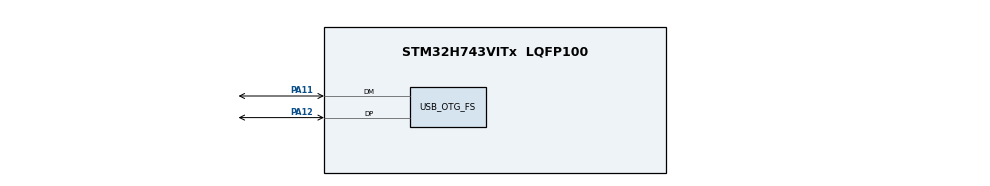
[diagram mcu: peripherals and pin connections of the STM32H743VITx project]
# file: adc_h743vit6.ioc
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Mcu.Family=STM32H7
Mcu.Name=STM32H743VITx
Mcu.Package=LQFP100
NVIC.OTG_FS_IRQn=true\:0\:0\:false\:false\:true\:false\:true
NVIC.PriorityGroup=NVIC_PRIORITYGROUP_4
PA11.Mode=Device_Only
PA11.Signal=USB_OTG_FS_DM
PA12.Mode=Device_Only
PA12.Signal=USB_OTG_FS_DP
ProjectManager.HeapSize=0x200
ProjectManager.StackSize=0x400
ProjectManager.TargetToolchain=STM32CubeIDE
RCC.ADCFreq_Value=129000000
RCC.APB1Freq_Value=64000000
RCC.APB2Freq_Value=64000000
RCC.APB3Freq_Value=64000000
RCC.APB4Freq_Value=64000000
RCC.CortexFreq_Value=64000000
RCC.HCLKFreq_Value=64000000
RCC.SYSCLKFreq_VALUE=64000000
RCC.USBCLockSelection=RCC_USBCLKSOURCE_HSI48
RCC.USBFreq_Value=48000000
USB_DEVICE.CLASS_NAME_FS=CDC
USB_DEVICE.VirtualMode-CDC_FS=Cdc
USB_DEVICE.VirtualModeFS=Cdc_FS
USB_OTG_FS.VirtualMode=Device_Only
VP_USB_DEVICE_VS_USB_DEVICE_CDC_FS.Mode=CDC_FS
board=custom

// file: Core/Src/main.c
/* USER CODE BEGIN Header */
/**
  ******************************************************************************
  * @file           : main.c
  * @brief          : Main program body
  ******************************************************************************
  * @attention
  *
  * <h2><center>&copy; Copyright (c) 2020 STMicroelectronics.
  * All rights reserved.</center></h2>
  *
  * This software component is licensed by ST under BSD 3-Clause license,
  * the "License"; You may not use this file except in compliance with the
  * License. You may obtain a copy of the License at:
  *                        opensource.org/licenses/BSD-3-Clause
  *
  ******************************************************************************
  */
/* USER CODE END Header */

#include "main.h"
#include "usb_device.h"

/* USER CODE BEGIN Includes */
#include "usbd_cdc_if.h"
/* USER CODE END Includes */

void SystemClock_Config(void);
static void MX_GPIO_Init(void);

int main(void)
{

  /* MCU Configuration--------------------------------------------------------*/

  /* Reset of all peripherals, Initializes the Flash interface and the Systick. */
  HAL_Init();

  /* Configure the system clock */
  SystemClock_Config();

  /* Initialize all configured peripherals */
  MX_GPIO_Init();
  MX_USB_DEVICE_Init();
  /* USER CODE BEGIN 2 */
  uint8_t a = 'a';
  /* USER CODE END 2 */

  /* Infinite loop */
  /* USER CODE BEGIN WHILE */
  while (1)
  {
	  CDC_Transmit_FS(&a, sizeof(a));
    /* USER CODE END WHILE */

  }
}

void SystemClock_Config(void)
{
  RCC_OscInitTypeDef RCC_OscInitStruct = {0};
  RCC_ClkInitTypeDef RCC_ClkInitStruct = {0};
  RCC_PeriphCLKInitTypeDef PeriphClkInitStruct = {0};

  /** Supply configuration update enable
  */
  HAL_PWREx_ConfigSupply(PWR_LDO_SUPPLY);
  /** Configure the main internal regulator output voltage
  */
  __HAL_PWR_VOLTAGESCALING_CONFIG(PWR_REGULATOR_VOLTAGE_SCALE3);

  while(!__HAL_PWR_GET_FLAG(PWR_FLAG_VOSRDY)) {}
  /** Initializes the CPU, AHB and APB busses clocks
  */
  RCC_OscInitStruct.OscillatorType = RCC_OSCILLATORTYPE_HSI48|RCC_OSCILLATORTYPE_HSI;
  RCC_OscInitStruct.HSIState = RCC_HSI_DIV1;
  RCC_OscInitStruct.HSICalibrationValue = RCC_HSICALIBRATION_DEFAULT;
  RCC_OscInitStruct.HSI48State = RCC_HSI48_ON;
  RCC_OscInitStruct.PLL.PLLState = RCC_PLL_NONE;
  if (HAL_RCC_OscConfig(&RCC_OscInitStruct) != HAL_OK)
  {
    Error_Handler();
  }
  /** Initializes the CPU, AHB and APB busses clocks
  */
  RCC_ClkInitStruct.ClockType = RCC_CLOCKTYPE_HCLK|RCC_CLOCKTYPE_SYSCLK
                              |RCC_CLOCKTYPE_PCLK1|RCC_CLOCKTYPE_PCLK2
                              |RCC_CLOCKTYPE_D3PCLK1|RCC_CLOCKTYPE_D1PCLK1;
  RCC_ClkInitStruct.SYSCLKSource = RCC_SYSCLKSOURCE_HSI;
  RCC_ClkInitStruct.SYSCLKDivider = RCC_SYSCLK_DIV1;
  RCC_ClkInitStruct.AHBCLKDivider = RCC_HCLK_DIV1;
  RCC_ClkInitStruct.APB3CLKDivider = RCC_APB3_DIV1;
  RCC_ClkInitStruct.APB1CLKDivider = RCC_APB1_DIV1;
  RCC_ClkInitStruct.APB2CLKDivider = RCC_APB2_DIV1;
  RCC_ClkInitStruct.APB4CLKDivider = RCC_APB4_DIV1;

  if (HAL_RCC_ClockConfig(&RCC_ClkInitStruct, FLASH_LATENCY_0) != HAL_OK)
  {
    Error_Handler();
  }
  PeriphClkInitStruct.PeriphClockSelection = RCC_PERIPHCLK_USB;
  PeriphClkInitStruct.UsbClockSelection = RCC_USBCLKSOURCE_HSI48;
  if (HAL_RCCEx_PeriphCLKConfig(&PeriphClkInitStruct) != HAL_OK)
  {
    Error_Handler();
  }
  /** Enable USB Voltage detector
  */
  HAL_PWREx_EnableUSBVoltageDetector();
}

static void MX_GPIO_Init(void)
{

  /* GPIO Ports Clock Enable */
  __HAL_RCC_GPIOA_CLK_ENABLE();

}

void Error_Handler(void)
{
}

/************************ (C) COPYRIGHT STMicroelectronics *****END OF FILE****/
